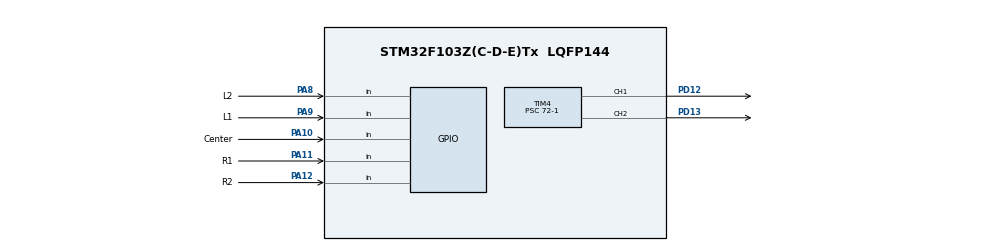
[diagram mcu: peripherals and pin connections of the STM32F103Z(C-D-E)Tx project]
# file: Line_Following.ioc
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Mcu.Family=STM32F1
Mcu.Name=STM32F103Z(C-D-E)Tx
Mcu.Package=LQFP144
NVIC.PriorityGroup=NVIC_PRIORITYGROUP_4
OSC_IN.Mode=HSE-External-Oscillator
OSC_IN.Signal=RCC_OSC_IN
OSC_OUT.Mode=HSE-External-Oscillator
OSC_OUT.Signal=RCC_OSC_OUT
PA10.GPIO_Label=Center
PA10.Signal=GPIO_Input
PA11.GPIO_Label=R1
PA11.Signal=GPIO_Input
PA12.GPIO_Label=R2
PA12.Signal=GPIO_Input
PA13.Mode=Serial_Wire
PA13.Signal=SYS_JTMS-SWDIO
PA14.Mode=Serial_Wire
PA14.Signal=SYS_JTCK-SWCLK
PA8.GPIO_Label=L2
PA8.GPIO_PuPd=GPIO_NOPULL
PA8.Signal=GPIO_Input
PA9.GPIO_Label=L1
PA9.Signal=GPIO_Input
PD12.Signal=S_TIM4_CH1
PD13.Signal=S_TIM4_CH2
ProjectManager.HeapSize=0x200
ProjectManager.StackSize=0x400
ProjectManager.TargetToolchain=MDK-ARM V5.32
RCC.APB1Freq_Value=8000000
RCC.APB2Freq_Value=8000000
SH.S_TIM4_CH1.0=TIM4_CH1,PWM Generation1 CH1
SH.S_TIM4_CH2.0=TIM4_CH2,PWM Generation2 CH2
TIM4.AutoReloadPreload=TIM_AUTORELOAD_PRELOAD_ENABLE
TIM4.Channel-PWM\ Generation1\ CH1=TIM_CHANNEL_1
TIM4.Channel-PWM\ Generation2\ CH2=TIM_CHANNEL_2
TIM4.Period=1000-1
TIM4.Prescaler=72-1
TIM4.Pulse-PWM\ Generation1\ CH1=500
TIM4.Pulse-PWM\ Generation2\ CH2=500
board=custom

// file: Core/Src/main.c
/* USER CODE BEGIN Header */
/**
  ******************************************************************************
  * @file           : main.c
  * @brief          : Main program body
  ******************************************************************************
  * @attention
  *
  * Copyright (c) 2023 STMicroelectronics.
  * All rights reserved.
  *
  * This software is licensed under terms that can be found in the LICENSE file
  * in the root directory of this software component.
  * If no LICENSE file comes with this software, it is provided AS-IS.
  *
  ******************************************************************************
  */
/* USER CODE END Header */
#include "main.h"
#include "tim.h"
#include "gpio.h"

/* USER CODE BEGIN Includes */
#include "greysensor.h"
/* USER CODE END Includes */

void SystemClock_Config(void);

int main(void)
{

  /* MCU Configuration--------------------------------------------------------*/

  /* Reset of all peripherals, Initializes the Flash interface and the Systick. */
  HAL_Init();

  /* Configure the system clock */
  SystemClock_Config();

  /* Initialize all configured peripherals */
  MX_GPIO_Init();
  MX_TIM4_Init();
  /* USER CODE BEGIN 2 */
  HAL_TIM_PWM_Start(&htim4,TIM_CHANNEL_1);
	HAL_TIM_PWM_Start(&htim4,TIM_CHANNEL_2);
  /* USER CODE END 2 */

  /* Infinite loop */
  /* USER CODE BEGIN WHILE */
  while (1)
  {
		get_error();
		__HAL_TIM_SetCompare(&htim4, TIM_CHANNEL_1, 500+error * 20);
		__HAL_TIM_SetCompare(&htim4, TIM_CHANNEL_2, 500-error * 20);
    /* USER CODE END WHILE */

  }
}

void SystemClock_Config(void)
{
  RCC_OscInitTypeDef RCC_OscInitStruct = {0};
  RCC_ClkInitTypeDef RCC_ClkInitStruct = {0};

  /** Initializes the RCC Oscillators according to the specified parameters
  * in the RCC_OscInitTypeDef structure.
  */
  RCC_OscInitStruct.OscillatorType = RCC_OSCILLATORTYPE_HSI;
  RCC_OscInitStruct.HSIState = RCC_HSI_ON;
  RCC_OscInitStruct.HSICalibrationValue = RCC_HSICALIBRATION_DEFAULT;
  RCC_OscInitStruct.PLL.PLLState = RCC_PLL_NONE;
  if (HAL_RCC_OscConfig(&RCC_OscInitStruct) != HAL_OK)
  {
    Error_Handler();
  }

  /** Initializes the CPU, AHB and APB buses clocks
  */
  RCC_ClkInitStruct.ClockType = RCC_CLOCKTYPE_HCLK|RCC_CLOCKTYPE_SYSCLK
                              |RCC_CLOCKTYPE_PCLK1|RCC_CLOCKTYPE_PCLK2;
  RCC_ClkInitStruct.SYSCLKSource = RCC_SYSCLKSOURCE_HSI;
  RCC_ClkInitStruct.AHBCLKDivider = RCC_SYSCLK_DIV1;
  RCC_ClkInitStruct.APB1CLKDivider = RCC_HCLK_DIV1;
  RCC_ClkInitStruct.APB2CLKDivider = RCC_HCLK_DIV1;

  if (HAL_RCC_ClockConfig(&RCC_ClkInitStruct, FLASH_LATENCY_0) != HAL_OK)
  {
    Error_Handler();
  }
}

void Error_Handler(void)
{
  __disable_irq();
  while (1)
  {
  }
}
